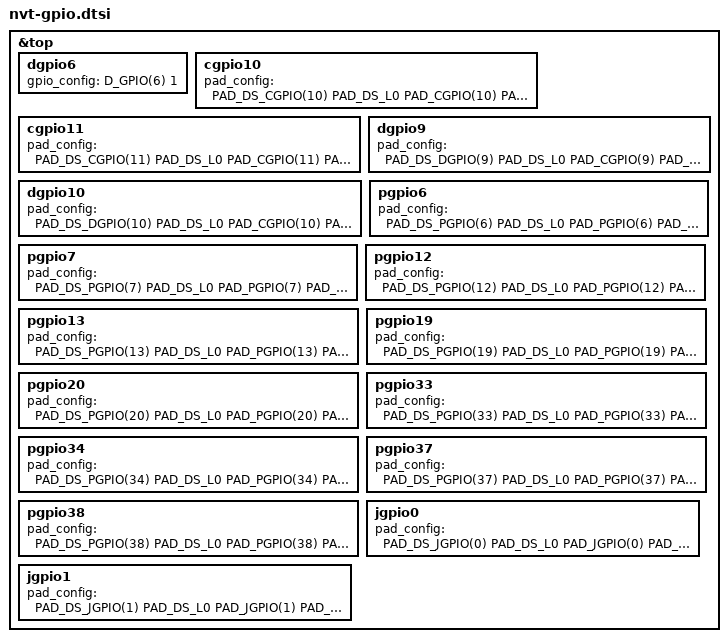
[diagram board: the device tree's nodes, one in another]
&top {
	dgpio6{gpio_config = <D_GPIO(6) 1>;};
	cgpio10{pad_config = <PAD_DS_CGPIO(10) PAD_DS_L0 PAD_CGPIO(10) PAD_PULLUP>;};
	cgpio11{pad_config = <PAD_DS_CGPIO(11) PAD_DS_L0 PAD_CGPIO(11) PAD_PULLUP>;};
	dgpio9{pad_config = <PAD_DS_DGPIO(9) PAD_DS_L0 PAD_CGPIO(9) PAD_PULLUP>;};
	dgpio10{pad_config = <PAD_DS_DGPIO(10) PAD_DS_L0 PAD_CGPIO(10) PAD_PULLUP>;};
	pgpio6{pad_config = <PAD_DS_PGPIO(6) PAD_DS_L0 PAD_PGPIO(6) PAD_PULLUP>;};
	pgpio7{pad_config = <PAD_DS_PGPIO(7) PAD_DS_L0 PAD_PGPIO(7) PAD_PULLUP>;};
	pgpio12{pad_config = <PAD_DS_PGPIO(12) PAD_DS_L0 PAD_PGPIO(12) PAD_PULLUP>;};
	pgpio13{pad_config = <PAD_DS_PGPIO(13) PAD_DS_L0 PAD_PGPIO(13) PAD_PULLUP>;};
	pgpio19{pad_config = <PAD_DS_PGPIO(19) PAD_DS_L0 PAD_PGPIO(19) PAD_PULLUP>;};
	pgpio20{pad_config = <PAD_DS_PGPIO(20) PAD_DS_L0 PAD_PGPIO(20) PAD_PULLUP>;};
	pgpio33{pad_config = <PAD_DS_PGPIO(33) PAD_DS_L0 PAD_PGPIO(33) PAD_PULLUP>;};
	pgpio34{pad_config = <PAD_DS_PGPIO(34) PAD_DS_L0 PAD_PGPIO(34) PAD_PULLUP>;};
	pgpio37{pad_config = <PAD_DS_PGPIO(37) PAD_DS_L0 PAD_PGPIO(37) PAD_PULLUP>;};
	pgpio38{pad_config = <PAD_DS_PGPIO(38) PAD_DS_L0 PAD_PGPIO(38) PAD_PULLUP>;};
	jgpio0{pad_config = <PAD_DS_JGPIO(0) PAD_DS_L0 PAD_JGPIO(0) PAD_PULLUP>;};
	jgpio1{pad_config = <PAD_DS_JGPIO(1) PAD_DS_L0 PAD_JGPIO(1) PAD_PULLUP>;};

	/*
	cgpio16{pad_config = <0x8010 0x80 0x10 0x1>;};
	cgpio17{pad_config = <0x8011 0x20 0x11 0x2>;};
	cgpio18{pad_config = <0x8012 0x20 0x12 0x2>;};
	cgpio19{pad_config = <0x8013 0x20 0x13 0x2>;};
	cgpio20{pad_config = <0x8014 0x20 0x14 0x2>;};
	cgpio21{pad_config = <0x8015 0x20 0x15 0x2>;};
	cgpio22{pad_config = <0x8016 0x80 0x16 0x1>;};
	cgpio23{pad_config = <0x8017 0x20 0x17 0x2>;};
	cgpio24{pad_config = <0x8018 0x20 0x18 0x2>;};
	cgpio25{pad_config = <0x8019 0x20 0x19 0x2>;};
	cgpio26{pad_config = <0x801A 0x20 0x1A 0x2>;};
	cgpio27{pad_config = <0x801B 0x20 0x1B 0x2>;};
	cgpio0{pad_config = <0x0 0x1000 0x0 0x2>;};
	cgpio1{pad_config = <0x1 0x1000 0x1 0x2>;};
	cgpio2{pad_config = <0x2 0x1000 0x2 0x2>;};
	cgpio3{pad_config = <0x3 0x1000 0x3 0x2>;};
	cgpio4{pad_config = <0x4 0x1000 0x4 0x2>;};
	cgpio5{pad_config = <0x5 0x1000 0x5 0x2>;};
	cgpio6{pad_config = <0x6 0x1000 0x6 0x2>;};
	cgpio7{pad_config = <0x7 0x1000 0x7 0x2>;};
	cgpio8{pad_config = <0x8 0x1000 0x8 0x2>;};
	cgpio9{pad_config = <0x1009 0x2000 0x9 0x2>;};
	cgpio10{pad_config = <0xA 0x1000 0xA 0x2>;};
	cgpio11{pad_config = <0xB 0x1000 0xB 0x2>;};
	cgpio12{pad_config = <0xC 0x1000 0xC 0x1>;};
	cgpio13{pad_config = <0xD 0x1000 0xD 0x1>;};
	cgpio14{pad_config = <0xE 0x1000 0xE 0x2>;};
	cgpio15{pad_config = <0xF 0x1000 0xF 0x2>;};
	cgpio16{pad_config = <0x8010 0x80 0x10 0x1>;};
	cgpio17{pad_config = <0x8011 0x20 0x11 0x2>;};
	cgpio18{pad_config = <0x8012 0x20 0x12 0x2>;};
	cgpio19{pad_config = <0x8013 0x20 0x13 0x2>;};
	cgpio20{pad_config = <0x8014 0x20 0x14 0x2>;};
	cgpio21{pad_config = <0x8015 0x20 0x15 0x2>;};
	cgpio22{pad_config = <0x8016 0x80 0x16 0x1>;};
	cgpio23{pad_config = <0x8017 0x20 0x17 0x2>;};
	cgpio24{pad_config = <0x8018 0x20 0x18 0x2>;};
	cgpio25{pad_config = <0x8019 0x20 0x19 0x2>;};
	cgpio26{pad_config = <0x801A 0x20 0x1A 0x2>;};
	cgpio27{pad_config = <0x801B 0x20 0x1B 0x2>;};
	cgpio28{pad_config = <0x101C 0x2000 0x1C 0x1>;};
	cgpio29{pad_config = <0x1D 0x1000 0x1D 0x2>;};
	cgpio30{pad_config = <0x1E 0x1000 0x1E 0x2>;};
	cgpio31{pad_config = <0x1F 0x1000 0x1F 0x2>;};
	cgpio32{pad_config = <0x20 0x1000 0x20 0x2>;};
	cgpio33{pad_config = <0x21 0x1000 0x21 0x2>;};
	sgpio0{pad_config = <0x1030 0x2000 0x64 0x1>;};
	sgpio1{pad_config = <0x2031 0x4000 0x65 0x1>;};
	sgpio2{pad_config = <0x2032 0x4000 0x66 0x1>;};
	sgpio3{pad_config = <0x2033 0x4000 0x67 0x1>;};
	sgpio4{pad_config = <0x2034 0x4000 0x68 0x1>;};
	sgpio5{pad_config = <0x1035 0x2000 0x69 0x1>;};
	sgpio6{pad_config = <0x2036 0x4000 0x6A 0x1>;};
	sgpio7{pad_config = <0x2037 0x4000 0x6B 0x1>;};
	sgpio8{pad_config = <0x38 0x1000 0x6C 0x2>;};
	sgpio9{pad_config = <0x39 0x1000 0x6D 0x2>;};
	sgpio10{pad_config = <0x3A 0x1000 0x6E 0x2>;};
	sgpio11{pad_config = <0x3B 0x1000 0x6F 0x2>;};
	pgpio0{pad_config = <0x40 0x1000 0x96 0x1>;};
	pgpio1{pad_config = <0x41 0x1000 0x97 0x1>;};
	pgpio2{pad_config = <0x42 0x1000 0x98 0x1>;};
	pgpio3{pad_config = <0x43 0x1000 0x99 0x1>;};
	pgpio4{pad_config = <0x44 0x1000 0x9A 0x1>;};
	pgpio5{pad_config = <0x45 0x1000 0x9B 0x1>;};
	pgpio6{pad_config = <0x46 0x1000 0x9C 0x1>;};
	pgpio7{pad_config = <0x47 0x1000 0x9D 0x1>;};
	pgpio8{pad_config = <0x48 0x1000 0x9E 0x1>;};
	pgpio9{pad_config = <0x49 0x1000 0x9F 0x1>;};
	pgpio10{pad_config = <0x4A 0x1000 0xA0 0x1>;};
	pgpio11{pad_config = <0x4B 0x1000 0xA1 0x1>;};
	pgpio12{pad_config = <0x4C 0x1000 0xA2 0x1>;};
	pgpio13{pad_config = <0x4D 0x1000 0xA3 0x1>;};
	pgpio14{pad_config = <0x4E 0x1000 0xA4 0x1>;};
	pgpio15{pad_config = <0x4F 0x1000 0xA5 0x1>;};
	pgpio16{pad_config = <0x50 0x1000 0xA6 0x1>;};
	pgpio17{pad_config = <0x51 0x1000 0xA7 0x1>;};
	pgpio18{pad_config = <0x52 0x1000 0xA8 0x1>;};
	pgpio19{pad_config = <0x53 0x1000 0xA9 0x1>;};
	pgpio20{pad_config = <0x1054 0x2000 0xAA 0x2>;};
	pgpio21{pad_config = <0x1055 0x2000 0xAB 0x1>;};
	pgpio22{pad_config = <0x1056 0x2000 0xAC 0x1>;};
	pgpio23{pad_config = <0x1057 0x2000 0xAD 0x1>;};
	pgpio24{pad_config = <0x58 0x1000 0xAE 0x2>;};
	pgpio25{pad_config = <0x59 0x1000 0xAF 0x2>;};
	pgpio26{pad_config = <0x5A 0x1000 0xB0 0x1>;};
	pgpio27{pad_config = <0x5B 0x1000 0xB1 0x1>;};
	pgpio28{pad_config = <0x5C 0x1000 0xB2 0x2>;};
	pgpio29{pad_config = <0x5D 0x1000 0xB3 0x2>;};
	pgpio30{pad_config = <0x5E 0x1000 0xB4 0x2>;};
	pgpio31{pad_config = <0x5F 0x1000 0xB5 0x2>;};
	pgpio32{pad_config = <0x60 0x1000 0xB6 0x1>;};
	pgpio33{pad_config = <0x61 0x1000 0xB7 0x1>;};
	pgpio34{pad_config = <0x62 0x1000 0xB8 0x2>;};
	pgpio35{pad_config = <0x63 0x1000 0xB9 0x2>;};
	pgpio36{pad_config = <0x64 0x1000 0xBA 0x2>;};
	pgpio37{pad_config = <0x65 0x1000 0xBB 0x2>;};
	pgpio38{pad_config = <0x66 0x1000 0xBC 0x2>;};
	pgpio39{pad_config = <0x67 0x1000 0xBD 0x1>;};
	pgpio40{pad_config = <0x68 0x1000 0xBE 0x1>;};
	pgpio41{pad_config = <0x69 0x1000 0xBF 0x2>;};
	pgpio42{pad_config = <0x206A 0x4000 0xC0 0x2>;};
	pgpio43{pad_config = <0x206B 0x4000 0xC1 0x2>;};
	pgpio44{pad_config = <0x206C 0x4000 0xC2 0x2>;};
	pgpio45{pad_config = <0x206D 0x4000 0xC3 0x2>;};
	pgpio46{pad_config = <0x206E 0x4000 0xC4 0x2>;};
	pgpio47{pad_config = <0x206F 0x4000 0xC5 0x1>;};
	lgpio0{pad_config = <0x1070 0x2000 0xFA 0x1>;};
	lgpio1{pad_config = <0x1071 0x2000 0xFB 0x1>;};
	lgpio2{pad_config = <0x1072 0x2000 0xFC 0x1>;};
	lgpio3{pad_config = <0x1073 0x2000 0xFD 0x1>;};
	lgpio4{pad_config = <0x1074 0x2000 0xFE 0x1>;};
	lgpio5{pad_config = <0x1075 0x2000 0xFF 0x1>;};
	lgpio6{pad_config = <0x1076 0x2000 0x100 0x1>;};
	lgpio7{pad_config = <0x1077 0x2000 0x101 0x1>;};
	lgpio8{pad_config = <0x1078 0x2000 0x102 0x1>;};
	lgpio9{pad_config = <0x1079 0x2000 0x103 0x1>;};
	lgpio10{pad_config = <0x7A 0x2000 0x104 0x1>;};
	lgpio11{pad_config = <0x7B 0x2000 0x105 0x1>;};
	lgpio12{pad_config = <0x7C 0x2000 0x106 0x1>;};
	lgpio13{pad_config = <0x7D 0x2000 0x107 0x1>;};
	lgpio14{pad_config = <0x7E 0x2000 0x108 0x1>;};
	lgpio15{pad_config = <0x7F 0x2000 0x109 0x1>;};
	lgpio16{pad_config = <0x80 0x2000 0x10A 0x1>;};
	lgpio17{pad_config = <0x81 0x2000 0x10B 0x1>;};
	lgpio18{pad_config = <0x82 0x2000 0x10C 0x1>;};
	lgpio19{pad_config = <0x83 0x2000 0x10D 0x1>;};
	lgpio20{pad_config = <0x84 0x2000 0x10E 0x1>;};
	lgpio21{pad_config = <0x85 0x2000 0x10F 0x1>;};
	lgpio22{pad_config = <0x86 0x2000 0x110 0x1>;};
	lgpio23{pad_config = <0x87 0x2000 0x111 0x1>;};
	lgpio24{pad_config = <0x88 0x2000 0x112 0x1>;};
	lgpio25{pad_config = <0x89 0x2000 0x113 0x1>;};
	lgpio26{pad_config = <0x8A 0x2000 0x114 0x1>;};
	lgpio27{pad_config = <0x8B 0x2000 0x115 0x1>;};
	lgpio28{pad_config = <0x8C 0x2000 0x116 0x1>;};
	lgpio29{pad_config = <0x8D 0x2000 0x117 0x1>;};
	lgpio30{pad_config = <0x8E 0x1000 0x118 0x2>;};
	lgpio31{pad_config = <0x8F 0x1000 0x119 0x1>;};
	lgpio32{pad_config = <0x90 0x1000 0x11A 0x1>;};
	dgpio0{pad_config = <0x40A0 0x8000 0x12C 0x2>;};
	dgpio1{pad_config = <0x40A1 0x8000 0x12D 0x2>;};
	dgpio2{pad_config = <0x40A2 0x8000 0x12E 0x1>;};
	dgpio3{pad_config = <0x40A3 0x8000 0x12F 0x1>;};
	dgpio4{pad_config = <0x40A4 0x8000 0x130 0x1>;};
	dgpio5{pad_config = <0x40A5 0x8000 0x131 0x1>;};
	dgpio6{pad_config = <0x20A6 0x4000 0x132 0x1>;};
	dgpio7{pad_config = <0x20A7 0x4000 0x133 0x1>;};
	dgpio8{pad_config = <0x20A8 0x4000 0x134 0x1>;};
	dgpio9{pad_config = <0x20A9 0x4000 0x135 0x1>;};
	dgpio10{pad_config = <0xAA 0x4000 0x136 0x1>;};
	dgpio11{pad_config = <0xAB 0x1000 0x137 0x1>;};
	dgpio12{pad_config = <0xAC 0x1000 0x138 0x1>;};
	cgpio0{gpio_config = <C_GPIO(0) 0>;};
	cgpio1{gpio_config = <C_GPIO(1) 0>;};
	cgpio2{gpio_config = <C_GPIO(2) 0>;};
	cgpio3{gpio_config = <C_GPIO(3) 0>;};
	cgpio4{gpio_config = <C_GPIO(4) 0>;};
	cgpio5{gpio_config = <C_GPIO(5) 0>;};
	cgpio6{gpio_config = <C_GPIO(6) 0>;};
	cgpio7{gpio_config = <C_GPIO(7) 0>;};
	cgpio8{gpio_config = <C_GPIO(8) 0>;};
	cgpio9{gpio_config = <C_GPIO(9) 0>;};
	cgpio10{gpio_config = <C_GPIO(10) 0>;};
	cgpio11{gpio_config = <C_GPIO(11) 0>;};
	cgpio12{gpio_config = <C_GPIO(12) 0>;};
	cgpio13{gpio_config = <C_GPIO(13) 0>;};
	cgpio14{gpio_config = <C_GPIO(14) 0>;};
	cgpio15{gpio_config = <C_GPIO(15) 0>;};
	cgpio16{gpio_config = <C_GPIO(16) 0>;};
	cgpio17{gpio_config = <C_GPIO(17) 0>;};
	cgpio18{gpio_config = <C_GPIO(18) 0>;};
	cgpio19{gpio_config = <C_GPIO(19) 0>;};
	cgpio20{gpio_config = <C_GPIO(20) 0>;};
	cgpio21{gpio_config = <C_GPIO(21) 0>;};
	cgpio22{gpio_config = <C_GPIO(22) 0>;};
	cgpio23{gpio_config = <C_GPIO(23) 0>;};
	cgpio24{gpio_config = <C_GPIO(24) 0>;};
	cgpio25{gpio_config = <C_GPIO(25) 0>;};
	cgpio26{gpio_config = <C_GPIO(26) 0>;};
	cgpio27{gpio_config = <C_GPIO(27) 0>;};
	cgpio28{gpio_config = <C_GPIO(28) 0>;};
	cgpio29{gpio_config = <C_GPIO(29) 0>;};
	cgpio30{gpio_config = <C_GPIO(30) 0>;};
	cgpio31{gpio_config = <C_GPIO(31) 0>;};
	cgpio32{gpio_config = <C_GPIO(32) 0>;};
	cgpio33{gpio_config = <C_GPIO(33) 0>;};
	sgpio0{gpio_config = <S_GPIO(0) 0>;};
	sgpio1{gpio_config = <S_GPIO(1) 0>;};
	sgpio2{gpio_config = <S_GPIO(2) 0>;};
	sgpio3{gpio_config = <S_GPIO(3) 0>;};
	sgpio4{gpio_config = <S_GPIO(4) 0>;};
	sgpio5{gpio_config = <S_GPIO(5) 0>;};
	sgpio6{gpio_config = <S_GPIO(6) 0>;};
	sgpio7{gpio_config = <S_GPIO(7) 0>;};
	sgpio8{gpio_config = <S_GPIO(8) 0>;};
	sgpio9{gpio_config = <S_GPIO(9) 0>;};
	sgpio10{gpio_config = <S_GPIO(10) 0>;};
	sgpio11{gpio_config = <S_GPIO(11) 0>;};
	pgpio0{gpio_config = <P_GPIO(0) 0>;};
	pgpio1{gpio_config = <P_GPIO(1) 0>;};
	pgpio2{gpio_config = <P_GPIO(2) 0>;};
	pgpio3{gpio_config = <P_GPIO(3) 0>;};
	pgpio4{gpio_config = <P_GPIO(4) 0>;};
	pgpio5{gpio_config = <P_GPIO(5) 0>;};
	pgpio6{gpio_config = <P_GPIO(6) 0>;};
	pgpio7{gpio_config = <P_GPIO(7) 0>;};
	pgpio8{gpio_config = <P_GPIO(8) 0>;};
	pgpio9{gpio_config = <P_GPIO(9) 0>;};
	pgpio10{gpio_config = <P_GPIO(10) 0>;};
	pgpio11{gpio_config = <P_GPIO(11) 0>;};
	pgpio12{gpio_config = <P_GPIO(12) 0>;};
	pgpio13{gpio_config = <P_GPIO(13) 0>;};
	pgpio14{gpio_config = <P_GPIO(14) 0>;};
	pgpio15{gpio_config = <P_GPIO(15) 0>;};
	pgpio16{gpio_config = <P_GPIO(16) 0>;};
	pgpio17{gpio_config = <P_GPIO(17) 0>;};
	pgpio18{gpio_config = <P_GPIO(18) 0>;};
	pgpio19{gpio_config = <P_GPIO(19) 0>;};
	pgpio20{gpio_config = <P_GPIO(20) 0>;};
	pgpio21{gpio_config = <P_GPIO(21) 0>;};
	pgpio22{gpio_config = <P_GPIO(22) 0>;};
	pgpio23{gpio_config = <P_GPIO(23) 0>;};
	pgpio24{gpio_config = <P_GPIO(24) 0>;};
	pgpio25{gpio_config = <P_GPIO(25) 0>;};
	pgpio26{gpio_config = <P_GPIO(26) 0>;};
	pgpio27{gpio_config = <P_GPIO(27) 0>;};
	pgpio28{gpio_config = <P_GPIO(28) 0>;};
	pgpio29{gpio_config = <P_GPIO(29) 0>;};
	pgpio30{gpio_config = <P_GPIO(30) 0>;};
	pgpio31{gpio_config = <P_GPIO(31) 0>;};
	pgpio32{gpio_config = <P_GPIO(32) 0>;};
	pgpio33{gpio_config = <P_GPIO(33) 0>;};
	pgpio34{gpio_config = <P_GPIO(34) 0>;};
	pgpio35{gpio_config = <P_GPIO(35) 0>;};
	pgpio36{gpio_config = <P_GPIO(36) 0>;};
	pgpio37{gpio_config = <P_GPIO(37) 0>;};
	pgpio38{gpio_config = <P_GPIO(38) 0>;};
	pgpio39{gpio_config = <P_GPIO(39) 0>;};
	pgpio40{gpio_config = <P_GPIO(40) 0>;};
	pgpio41{gpio_config = <P_GPIO(41) 0>;};
	pgpio42{gpio_config = <P_GPIO(42) 0>;};
	pgpio43{gpio_config = <P_GPIO(43) 0>;};
	pgpio44{gpio_config = <P_GPIO(44) 0>;};
	pgpio45{gpio_config = <P_GPIO(45) 0>;};
	pgpio46{gpio_config = <P_GPIO(46) 0>;};
	pgpio47{gpio_config = <P_GPIO(47) 0>;};
	lgpio0{gpio_config = <L_GPIO(0) 0>;};
	lgpio1{gpio_config = <L_GPIO(1) 0>;};
	lgpio2{gpio_config = <L_GPIO(2) 0>;};
	lgpio3{gpio_config = <L_GPIO(3) 0>;};
	lgpio4{gpio_config = <L_GPIO(4) 0>;};
	lgpio5{gpio_config = <L_GPIO(5) 0>;};
	lgpio6{gpio_config = <L_GPIO(6) 0>;};
	lgpio7{gpio_config = <L_GPIO(7) 0>;};
	lgpio8{gpio_config = <L_GPIO(8) 0>;};
	lgpio9{gpio_config = <L_GPIO(9) 0>;};
	lgpio10{gpio_config = <L_GPIO(10) 0>;};
	lgpio11{gpio_config = <L_GPIO(11) 0>;};
	lgpio12{gpio_config = <L_GPIO(12) 0>;};
	lgpio13{gpio_config = <L_GPIO(13) 0>;};
	lgpio14{gpio_config = <L_GPIO(14) 0>;};
	lgpio15{gpio_config = <L_GPIO(15) 0>;};
	lgpio16{gpio_config = <L_GPIO(16) 0>;};
	lgpio17{gpio_config = <L_GPIO(17) 0>;};
	lgpio18{gpio_config = <L_GPIO(18) 0>;};
	lgpio19{gpio_config = <L_GPIO(19) 0>;};
	lgpio20{gpio_config = <L_GPIO(20) 0>;};
	lgpio21{gpio_config = <L_GPIO(21) 0>;};
	lgpio22{gpio_config = <L_GPIO(22) 0>;};
	lgpio23{gpio_config = <L_GPIO(23) 0>;};
	lgpio24{gpio_config = <L_GPIO(24) 0>;};
	lgpio25{gpio_config = <L_GPIO(25) 0>;};
	lgpio26{gpio_config = <L_GPIO(26) 0>;};
	lgpio27{gpio_config = <L_GPIO(27) 0>;};
	lgpio28{gpio_config = <L_GPIO(28) 0>;};
	lgpio29{gpio_config = <L_GPIO(29) 0>;};
	lgpio30{gpio_config = <L_GPIO(30) 0>;};
	lgpio31{gpio_config = <L_GPIO(31) 0>;};
	lgpio32{gpio_config = <L_GPIO(32) 0>;};
	dgpio0{gpio_config = <D_GPIO(0) 0>;};
	dgpio1{gpio_config = <D_GPIO(1) 1>;};
	dgpio2{gpio_config = <D_GPIO(2) 0>;};
	dgpio3{gpio_config = <D_GPIO(3) 0>;};
	dgpio4{gpio_config = <D_GPIO(4) 0>;};
	dgpio5{gpio_config = <D_GPIO(5) 0>;};
	dgpio6{gpio_config = <D_GPIO(6) 0>;};
	dgpio7{gpio_config = <D_GPIO(7) 0>;};
	dgpio8{gpio_config = <D_GPIO(8) 0>;};
	dgpio9{gpio_config = <D_GPIO(9) 0>;};
	dgpio10{gpio_config = <D_GPIO(10) 0>;};
	dgpio11{gpio_config = <D_GPIO(11) 0>;};
	dgpio12{gpio_config = <D_GPIO(12) 0>;};
	*/
};
